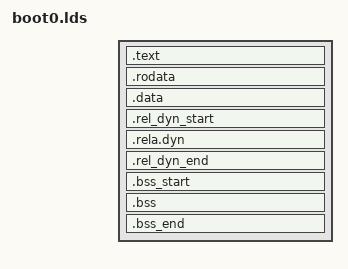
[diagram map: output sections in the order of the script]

OUTPUT_FORMAT("elf64-littleaarch64", "elf64-littleaarch64", "elf64-littleaarch64")
OUTPUT_ARCH(aarch64)
ENTRY(_start)
SECTIONS
{
	/* . = 0x400000; */

	/* . = ALIGN(64); */
	.text :
	{
		../obj/start.o (.text*)
		*(.text*)
	}

	. = ALIGN(8);
	.rodata : { *(SORT_BY_ALIGNMENT(SORT_BY_NAME(.rodata*))) }

	. = ALIGN(8);
	.data : {
		*(.data*)
	}

	. = ALIGN(64);
        _edata = .;

	. = ALIGN(64);

	.rel_dyn_start :
	{
		*(.__rel_dyn_start)
	}

	.rela.dyn : {
		*(.rela*)
	}

	.rel_dyn_end :
	{
		*(.__rel_dyn_end)
	}

	. = ALIGN(16);

	_end = .;

	. = ALIGN(64);

        __bss_start__ = .;
	.bss_start : {
		KEEP(*(.__bss_start));
	}

	.bss : {
		*(.bss*)
		 . = ALIGN(8);
	}

	.bss_end : {
		KEEP(*(.__bss_end));
	}
	. = ALIGN(64);

        __bss_end__ = .;

	/DISCARD/ : { *(.dynsym) }
	/DISCARD/ : { *(.dynstr*) }
	/DISCARD/ : { *(.dynamic*) }
	/DISCARD/ : { *(.plt*) }
	/DISCARD/ : { *(.interp*) }
	/DISCARD/ : { *(.gnu*) }
}
